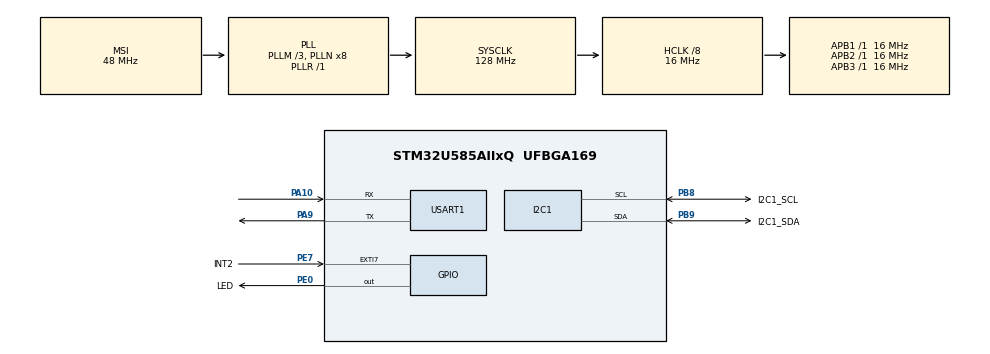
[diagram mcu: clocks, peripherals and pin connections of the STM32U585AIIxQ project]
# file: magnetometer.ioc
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CORTEX_M33_NS.userName=CORTEX_M33
I2C1.Timing=0x00303D5B
Mcu.Family=STM32U5
Mcu.Name=STM32U585AIIxQ
Mcu.Package=UFBGA169
NVIC.EXTI7_IRQn=true\:0\:0\:false\:false\:true\:true\:true\:true
NVIC.PriorityGroup=NVIC_PRIORITYGROUP_4
PA10.Mode=Asynchronous
PA10.Signal=USART1_RX
PA9.Mode=Asynchronous
PA9.Signal=USART1_TX
PB8.GPIO_Label=I2C1_SCL
PB8.Mode=I2C
PB8.Signal=I2C1_SCL
PB9.GPIO_Label=I2C1_SDA
PB9.Mode=I2C
PB9.Signal=I2C1_SDA
PE0.GPIO_Label=LED
PE0.Signal=GPIO_Output
PE7.GPIO_Label=INT2
PE7.Signal=GPXTI7
PWR.PowerMode=PWR_SMPS_SUPPLY
ProjectManager.HeapSize=0x200
ProjectManager.StackSize=0x400
ProjectManager.TargetToolchain=STM32CubeIDE
RCC.ADCFreq_Value=16000000
RCC.AHBCLKDivider=RCC_SYSCLK_DIV8
RCC.AHBFreq_Value=16000000
RCC.APB1Freq_Value=16000000
RCC.APB1TimFreq_Value=16000000
RCC.APB2Freq_Value=16000000
RCC.APB2TimFreq_Value=16000000
RCC.APB3Freq_Value=16000000
RCC.CortexFreq_Value=16000000
RCC.DACCLockSelectionVirtual=RCC_DAC1CLKSOURCE_LSI
RCC.DACCLockSelectionVirtualString=RCC_DAC1CLKSOURCE_LSI
RCC.EPOD_VALUE=48000000
RCC.HCLKFreq_Value=16000000
RCC.HSE_VALUE=16000000
RCC.HSI48_VALUE=48000000
RCC.HSI_VALUE=16000000
RCC.LSE_VALUE=32768
RCC.LSIDIV_VALUE=32000
RCC.MSIClockRange=RCC_MSIRANGE_0
RCC.MSI_VALUE=48000000
RCC.PLL1R=1
RCC.PLLFRACN=0
RCC.PLLM=3
RCC.PLLN=8
RCC.SYSCLKFreq_VALUE=128000000
RCC.SYSCLKSource=RCC_SYSCLKSOURCE_PLLCLK
RCC.USBFreq_Value=48000000
RCC.VCOOutputFreq_Value=128000000
USART1.VirtualMode-Asynchronous=VM_ASYNC
VP_LPBAMQUEUE_VS_QUEUE.Mode=QUEUEMODE
VP_LPBAM_VS_SIG1.Mode=SmartRun
VP_LPBAM_VS_SIG4.Mode=LPDMA1
VP_PWR_VS_LPOM.Mode=PowerOptimisation
VP_PWR_VS_SECSignals.Mode=Security/Privilege
board=B-U585I-IOT02A

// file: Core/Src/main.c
/* USER CODE BEGIN Header */
/**
  ******************************************************************************
  * @file           : main.c
  * @brief          : Main program body
  ******************************************************************************
  * @attention
  *
  * Copyright (c) 2022 STMicroelectronics.
  * All rights reserved.
  *
  * This software is licensed under terms that can be found in the LICENSE file
  * in the root directory of this software component.
  * If no LICENSE file comes with this software, it is provided AS-IS.
  *
  ******************************************************************************
  */
/* USER CODE END Header */
#include "main.h"
#include "i2c.h"
#include "usart.h"
#include "gpio.h"

/* USER CODE BEGIN Includes */
#include "magnetometer.h"
/* USER CODE END Includes */

void SystemClock_Config(void);
static void SystemPower_Config(void);

int main(void)
{

  /* MCU Configuration--------------------------------------------------------*/

  /* Reset of all peripherals, Initializes the Flash interface and the Systick. */
  HAL_Init();

  /* Configure the system clock */
  SystemClock_Config();

  /* Configure the System Power */
  SystemPower_Config();

  /* Initialize all configured peripherals */
  MX_GPIO_Init();
  MX_I2C1_Init();
  MX_USART1_UART_Init();
  /* USER CODE BEGIN 2 */
  	  	  i2c_scanner();
  	  	  bsp_init(); //initialize magnetometer

  /* USER CODE END 2 */

  /* Infinite loop */
  while (1)
  {

    /* USER CODE BEGIN 3 */

	  bsp_process();

  }
  /* USER CODE END 3 */
}

void SystemClock_Config(void)
{
  RCC_OscInitTypeDef RCC_OscInitStruct = {0};
  RCC_ClkInitTypeDef RCC_ClkInitStruct = {0};

  /** Configure the main internal regulator output voltage
  */
  if (HAL_PWREx_ControlVoltageScaling(PWR_REGULATOR_VOLTAGE_SCALE1) != HAL_OK)
  {
    Error_Handler();
  }

  /** Initializes the CPU, AHB and APB buses clocks
  */
  RCC_OscInitStruct.OscillatorType = RCC_OSCILLATORTYPE_MSI;
  RCC_OscInitStruct.MSIState = RCC_MSI_ON;
  RCC_OscInitStruct.MSICalibrationValue = RCC_MSICALIBRATION_DEFAULT;
  RCC_OscInitStruct.MSIClockRange = RCC_MSIRANGE_0;
  RCC_OscInitStruct.PLL.PLLState = RCC_PLL_ON;
  RCC_OscInitStruct.PLL.PLLSource = RCC_PLLSOURCE_MSI;
  RCC_OscInitStruct.PLL.PLLMBOOST = RCC_PLLMBOOST_DIV4;
  RCC_OscInitStruct.PLL.PLLM = 3;
  RCC_OscInitStruct.PLL.PLLN = 8;
  RCC_OscInitStruct.PLL.PLLP = 2;
  RCC_OscInitStruct.PLL.PLLQ = 2;
  RCC_OscInitStruct.PLL.PLLR = 1;
  RCC_OscInitStruct.PLL.PLLRGE = RCC_PLLVCIRANGE_1;
  RCC_OscInitStruct.PLL.PLLFRACN = 0;
  if (HAL_RCC_OscConfig(&RCC_OscInitStruct) != HAL_OK)
  {
    Error_Handler();
  }

  /** Initializes the CPU, AHB and APB buses clocks
  */
  RCC_ClkInitStruct.ClockType = RCC_CLOCKTYPE_HCLK|RCC_CLOCKTYPE_SYSCLK
                              |RCC_CLOCKTYPE_PCLK1|RCC_CLOCKTYPE_PCLK2
                              |RCC_CLOCKTYPE_PCLK3;
  RCC_ClkInitStruct.SYSCLKSource = RCC_SYSCLKSOURCE_PLLCLK;
  RCC_ClkInitStruct.AHBCLKDivider = RCC_SYSCLK_DIV8;
  RCC_ClkInitStruct.APB1CLKDivider = RCC_HCLK_DIV1;
  RCC_ClkInitStruct.APB2CLKDivider = RCC_HCLK_DIV1;
  RCC_ClkInitStruct.APB3CLKDivider = RCC_HCLK_DIV1;

  if (HAL_RCC_ClockConfig(&RCC_ClkInitStruct, FLASH_LATENCY_0) != HAL_OK)
  {
    Error_Handler();
  }
}

/**
  * @brief Power Configuration
  * @retval None
  */
static void SystemPower_Config(void)
{

  /*
   * Switch to SMPS regulator instead of LDO
   */
  if (HAL_PWREx_ConfigSupply(PWR_SMPS_SUPPLY) != HAL_OK)
  {
    Error_Handler();
  }
}

void Error_Handler(void)
{
  __disable_irq();
  while (1)
  {
  }
}
